# DA1469x register map
Vendor: Dialog; Series: DA1469x; File version: 1.2
CPU: CM33 r1p0, little endian, no MPU, FPU, 3 interrupt priority bits
Registers are 32-bit, read-write, reset 0x0 unless marked. A register's access mark holds for its fields unless they carry their own. Offsets are from the block's base; [hi:lo] are bit positions.

## QSPIC2 — QSPIC2 registers
Base 0x34000000
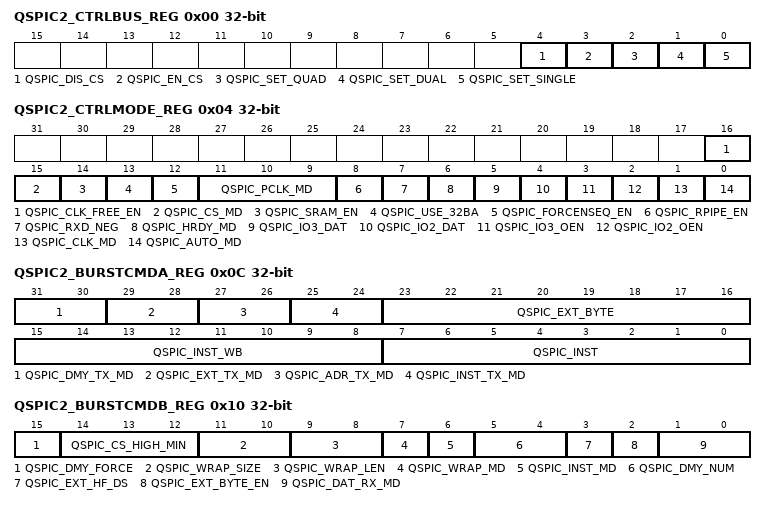
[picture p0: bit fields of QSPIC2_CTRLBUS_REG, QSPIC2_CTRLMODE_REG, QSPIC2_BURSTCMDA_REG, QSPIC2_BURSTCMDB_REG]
0x00 QSPIC2_CTRLBUS_REG — SPI Bus control register for the Manual mode
  [4] QSPIC_DIS_CS wo — Write 1 to disable the chip select (active low) when the controller is in Manual mode.
  [3] QSPIC_EN_CS wo — Write 1 to enable the chip select (active low) when the controller is in Manual mode.
  [2] QSPIC_SET_QUAD wo — Write 1 to set the bus mode in Quad mode when the controller is in Manual mode.
  [1] QSPIC_SET_DUAL wo — Write 1 to set the bus mode in Dual mode when the controller is in Manual mode.
  [0] QSPIC_SET_SINGLE wo — Write 1 to set the bus mode in Single SPI mode when the controller is in Manual mode.
0x04 QSPIC2_CTRLMODE_REG — Mode control register
  [16] QSPIC_CLK_FREE_EN — Controls the behavior of the QSPI_SCK when the QSPI_CS is high and the QSPIC_CS_MD=1. 0: Is produced one QSPI_SCK clock pulse after each 0 to 1 transition in the QSPI_CS. 1: The QSPI_SCK clock remains always active, while the QSPI_CS is inactive. This setting has meaning only when the QSPIC_CS_MD=1.
  [15] QSPIC_CS_MD — Controls the clock edge with which is produced the QSPI_CS signal. 0: The QSPI_CS is produced with the rising edge of the QSPI_SCK. The QSPI_SCK is always inactive while the QSPI_CS is high. 1: The QSPI_CS is produced with the falling edge of the QSPI_SCK. The behavior of the QSPI_SCK while the QSPI_CS is high, is controlled by the QSPIC_CLK_FREE_EN.
  [14] QSPIC_SRAM_EN — Defines the type of the external device that is connected on the QSPIC controller 0: The external memory device is a serial Flash 1: The external memory device is a serial SRAM When the external device is a serial SRAM, the erase suspend/ resume functionality of the controller is disabled. In this case the writing of the QSPIC_ERASECTRL_REG[QSPIC_ERASE_EN] bit has no effect. Also, the memory space where the external device is mapped, is considered as writable.
  [13] QSPIC_USE_32BA — Controls the length of the address that the external memory device uses. 0: The external memory device uses 24 bits address. 1: The external memory device uses 32 bits address. The controller uses this bit in order to decide the number of the address bytes that has to transfer to the external device during Auto mode.
  [12] QSPIC_FORCENSEQ_EN — Controls the way with which is addressed by the QSPI controller a burst request from the AMBA bus. 0: The controller translates a burst access on the AMBA bus as a burst access on the QSPI bus. That results to the minimum number of command/address phases. 1: The controller will split a burst access on the AMBA bus into a number of single accesses on the QSPI bus. That results to a separate command for each beat of the burst. E.g a 4-beat word incremental AMBA read access will be split into 4 different sequences on the QSPI bus: command/address/extra clock/read data. The QSPI_CS will be low only for the time that is needed for each of these single access. This configuration bit is usefull when the clock frequency of the QSPI bus is much higher than the clock of the AMBA bus. In this case the interval for which the CS remains low is minimized, achieving lower power dissipation with respect of the case where the QSPIC_FORCENSEQ_EN=0, at cost of performance.
  [11:9] QSPIC_PCLK_MD — Controls the read pipe clock delay relative to the falling edge of QSPI_SCK. Refer to QSPI Timing for timing parameters
  [8] QSPIC_RPIPE_EN — Controls the use of the data read pipe. 0: The read pipe is disabled, the sampling clock is defined according to the QSPIC_RXD_NEG setting. 1: The read pipe is enabled. The delay of the sampling clock is defined according to the QSPI_PCLK_MD setting. (Recommended)
  [7] QSPIC_RXD_NEG — Defines the clock edge that is used for the capturing of the received data, when the read pipe is not active (QSPIC_RPIPE_EN = 0). 0: Sampling of the received data with the positive edge of the QSPI_SCK 1: Sampling of the received data with the negative edge of the QSPI_SCK The internal QSPI_SCK clock that is used by the controller for the capturing of the received data has a skew in respect of the QSPI_SCK that is received by the external memory device. In order to be improved the timing requirements of the read path, the controller supports a read pipe register with programmable clock delay. See also the QSPIC_RPIPE_EN register.
  [6] QSPIC_HRDY_MD — This configuration bit is useful when the frequency of the QSPI clock is much lower than the clock of the AMBA bus, in order to not locks the AMBA bus for a long time. 0: Adds wait states via hready signal when an access is performed on the QSPIC_WRITEDATA, QSPIC_READDATA and QSPIC_DUMMYDATA registers. It is not needed to checked the QSPIC_BUSY of the QSPIC_STATUS_REG. 1: The controller don't adds wait states via the hready signal, when is performed access on the QSPIC_WRITEDATA, QSPIC_READDATA and QSPIC_DUMMYDATA registers. The QSPIC_BUSY bit of the QSPIC_STATUS_REG must be checked in order to be detected the completion of the requested access. It is applicable only when the controller is in Manual mode. In the case of the Auto mode, the controller always adds wait states via the hready signal.
  [5] QSPIC_IO3_DAT — The value of QSPI_IO3 pad if QSPI_IO3_OEN is 1
  [4] QSPIC_IO2_DAT — The value of QSPI_IO2 pad if QSPI_IO2_OEN is 1
  [3] QSPIC_IO3_OEN — QSPI_IO3 output enable. Use this only in SPI or Dual SPI mode to control /HOLD signal. When the Auto Mode is selected (QSPIC_AUTO_MD = 1) and the QUAD SPI is used, set this bit to zero. 0: The QSPI_IO3 pad is input. 1: The QSPI_IO3 pad is output.
  [2] QSPIC_IO2_OEN — QSPI_IO2 output enable. Use this only in SPI or Dual SPI mode to control /WP signal. When the Auto Mode is selected (QSPIC_AUTO_MD = 1) and the QUAD SPI is used, set this bit to zero. 0: The QSPI_IO2 pad is input. 1: The QSPI_IO2 pad is output.
  [1] QSPIC_CLK_MD — Mode of the generated QSPI_SCK clock 0: Use Mode 0 for the QSPI_CLK. The QSPI_SCK is low when QSPI_CS is high. 1: Use Mode 3 for the QSPI_CLK. The QSPI_SCK is high when QSPI_CS is high. See also the register QSPIC_CS_MD and the QSPIC_CLK_FREE_EN
  [0] QSPIC_AUTO_MD — Mode of operation 0: The Manual Mode is selected. 1: The Auto Mode is selected. During an erasing the QSPIC_AUTO_MD goes in read only mode (see QSPIC_ERASE_EN)
0x08 QSPIC2_RECVDATA_REG (reset mask 0x7FFFFFFF) — Received data for the Manual mode
  [31:0] QSPIC_RECVDATA ro — This register contains the received data when the QSPIC_READDATA_REG register is used in Manual mode, in order to be retrieved data from the external memory device and QSPIC_HRDY_MD=1 && QSPIC_BUSY=0.
0x0C QSPIC2_BURSTCMDA_REG (reset mask 0x7FFFFFFF) — The way of reading in Auto mode (command register A)
  [31:30] QSPIC_DMY_TX_MD — It describes the mode of the SPI bus during the Dummy bytes phase. 0x0: Single SPI 0x1: Dual 0x2: Quad 0x3: Reserved
  [29:28] QSPIC_EXT_TX_MD — It describes the mode of the SPI bus during the Extra Byte phase. 0x0: Single SPI 0x1: Dual 0x2: Quad 0x3: Reserved
  [27:26] QSPIC_ADR_TX_MD — It describes the mode of the SPI bus during the address phase. 0x0: Single SPI 0x1: Dual 0x2: Quad 0x3: Reserved
  [25:24] QSPIC_INST_TX_MD — It describes the mode of the SPI bus during the instruction phase. 0x0: Single SPI 0x1: Dual 0x2: Quad 0x3: Reserved
  [23:16] QSPIC_EXT_BYTE — The value of an extra byte which will be transferred after address (only if QSPIC_EXT_BYTE_EN= 1). Usually this is the Mode Bits in Dual/Quad SPI I/O instructions.
  [15:8] QSPIC_INST_WB — Instruction Value for Wrapping Burst. This value is the selected instruction when QSPIC_WRAP_MD is equal to 1 and the access is a wrapping burst of length and size described by the bit fields QSPIC_WRAP_LEN and QSPIC_WRAP_SIZE respectively.
  [7:0] QSPIC_INST — Instruction Value for Incremental Burst or Single read access. This value is the selected instruction at the cases of incremental burst or single read access. Also this value is used when a wrapping burst is not supported (QSPIC_WRAP_MD)
0x10 QSPIC2_BURSTCMDB_REG — The way of reading in Auto mode (command register B)
  [15] QSPIC_DMY_FORCE — By setting this bit, the number of dummy bytes is forced to be equal to 3. In this case the QSPIC_DMY_NUM field is overruled and has no function. 0: The number of dummy bytes is controlled by the QSPIC_DMY_NUM field 1: Three dummy bytes are used. The QSPIC_DMY_NUM is overruled.
  [14:12] QSPIC_CS_HIGH_MIN — Between the transmission of two different instructions to the flash memory, the qspi bus stays in idle state (QSPI_CS high) for at least this number of QSPI_SCK clock cycles. See the QSPIC_ERS_CS_HI and the QSPIC_WR_CS_HIGH_MIN registers for some exceptions.
  [11:10] QSPIC_WRAP_SIZE — It describes the selected data size of a wrapping burst (QSPIC_WRAP_MD). 0x0: Byte access (8-bits) 0x1: Half word access (16 bits) 0x2: Word access (32-bits) 0x3: Reserved
  [9:8] QSPIC_WRAP_LEN — It describes the selected length of a wrapping burst (QSPIC_WRAP_MD). 0x0: 4 beat wrapping burst 0x1: 8 beat wrapping burst 0x2: 16 beat wrapping burst 0x3: Reserved
  [7] QSPIC_WRAP_MD — Wrap mode 0: The QSPIC_INST is the selected instruction at any access. 1: The QSPIC_INST_WB is the selected instruction at any wrapping burst access of length and size described by the registers QSPIC_WRAP_LEN and QSPIC_WRAP_SIZE respectively. In all other cases the QSPIC_INST is the selected instruction. Use this feature only when the serial FLASH memory supports a special instruction for wrapping burst access.
  [6] QSPIC_INST_MD — Instruction mode 0: Transmit instruction at any burst access. 1: Transmit instruction only in the first access after the selection of Auto Mode.
  [5:4] QSPIC_DMY_NUM — Number of Dummy Bytes 0x0: Zero Dummy Bytes (Don't Send Dummy Bytes) 0x1: Send 1 Dummy Byte 0x2: Send 2 Dummy Bytes 0x3: Send 4 Dummy Bytes When QSPIC_DMY_FORCE is enabled, the QSPIC_DMY_NUM is overruled. In this case the number of dummy bytes is defined by the QSPIC_DMY_FORCE and is equal to 3, independent of the value of the QSPIC_DMY_NUM.
  [3] QSPIC_EXT_HF_DS — Extra Half Disable Output 0: if QSPIC_EXT_BYTE_EN=1 then transmit the complete QSPIC_EXT_BYTE 1: if QSPIC_EXT_BYTE_EN=1 then disable (hi-z) output during the transmission of bits [3:0] of QSPIC_EXT_BYTE
  [2] QSPIC_EXT_BYTE_EN — Extra Byte Enable 0: Don't Send QSPIC_EXT_BYTE 1: Send QSPIC_EXT_BYTE
  [1:0] QSPIC_DAT_RX_MD — It describes the mode of the SPI bus during the data phase. 0x0: Single SPI 0x1: Dual 0x2: Quad 0x3: Reserved
0x14 QSPIC2_STATUS_REG — The status register of the QSPI controller
  [0] QSPIC_BUSY ro — The status of the SPI Bus. 0: The SPI Bus is idle 1: The SPI Bus is active. Read data, write data or dummy data activity is in progress. Has meaning only in Manual mode and only when QSPIC_HRDY_MD = 1.
0x18 QSPIC2_WRITEDATA_REG (reset mask 0x7FFFFFFF) — Write data to SPI Bus for the Manual mode
  [31:0] QSPIC_WRITEDATA wo — Writing to this register is generating a data transfer from the controller to the external memory device. The data written in this register, is then transferred to the memory using the selected mode of the SPI bus (SPI, Dual SPI, Quad SPI). The data size of the access to this register can be 32-bits / 16-bits/ 8-bits and is equal to the number of the transferred bits. This register has meaning only when the controller is in Manual mode.
0x1C QSPIC2_READDATA_REG (reset mask 0x7FFFFFFF) — Read data from SPI Bus for the Manual mode
  [31:0] QSPIC_READDATA ro — A read access at this register generates a data transfer from the external memory device to the QSPIC controller. The data is transferred using the selected mode of the SPI bus (SPI, Dual SPI, Quad SPI). The data size of the access to this register can be 32-bits / 16-bits / 8-bits and is equal to the number of the transferred bits. This register has meaning only when the controller is in Manual mode.
0x20 QSPIC2_DUMMYDATA_REG (reset mask 0x7FFFFFFF) — Send dummy clocks to SPI Bus for the Manual mode
  [31:0] QSPIC_DUMMYDATA wo — Writing to this register generates a number of clock pulses to the SPI bus. During the last clock of this activity in the SPI bus, the QSPI_IOx data pads are in hi-z state. The data size of the access to this register can be 32-bits / 16-bits/ 8-bits. The number of generated pulses is equal to: (size of AHB bus access) / (size of SPI bus). The size of SPI bus is equal to 1, 2 or 4 for Single, Dual or Quad SPI mode respectively. This register has meaning only when the controller is in Manual mode.
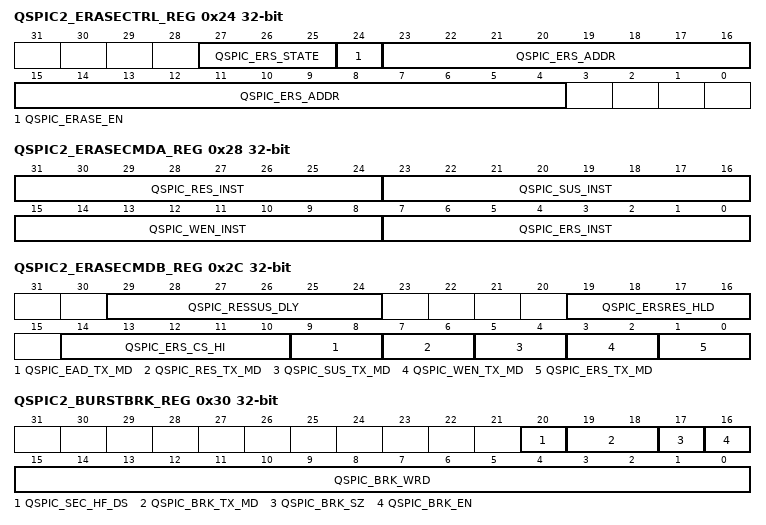
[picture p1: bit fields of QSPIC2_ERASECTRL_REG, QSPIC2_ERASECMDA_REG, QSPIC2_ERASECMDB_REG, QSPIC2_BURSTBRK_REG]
0x24 QSPIC2_ERASECTRL_REG — Erase control register
  [27:25] QSPIC_ERS_STATE ro — It shows the progress of sector/block erasing (read only). 0x0: No Erase. 0x1: Pending erase request 0x2: Erase procedure is running 0x3: Suspended Erase procedure 0x4: Finishing the Erase procedure 0x5..0x7: Reserved
  [24] QSPIC_ERASE_EN — This bit has meaning only when the external device is a serial FLASH (QSPIC_SRAM_EN=0). During Manual mode (QSPIC_AUTO_MD = 0) : This bit is in read only mode. During Auto mode (QSPIC_AUTO_MD = 1). To request the erasing of the block/sector (QSPIC_ERS_ADDR, 12'b0) write 1 to this bit. This bit is cleared automatically with the end of the erasing. Until the end of erasing the QSPIC_ERASE_EN remains in read only mode. During the same period of time the controller remains in Auto Mode (QSPIC_AUTO_MD goes in read only mode). In the case where the external device is a serial SRAM (QSPIC_SRAM_EN=1) this bit is in read only mode.
  [23:4] QSPIC_ERS_ADDR — Defines the address of the block/sector that is requested to be erased. If QSPIC_USE_32BA = 0 (24 bits addressing), bits QSPIC_ERASECTRL_REG[23-12] determine the block/ sector address bits [23-12]. QSPIC_ERASECTRL_REG[11-4] are ignored by the controller. If QSPIC_USE_32BA = 1 (32 bits addressing) bits QSPIC_ERASECTRL_REG[23-4] determine the block / sectors address bits [31:12]
0x28 QSPIC2_ERASECMDA_REG (reset mask 0x7FFFFFFF) — The way of erasing in Auto mode (command register A)
  [31:24] QSPIC_RES_INST — The code value of the erase resume instruction
  [23:16] QSPIC_SUS_INST — The code value of the erase suspend instruction.
  [15:8] QSPIC_WEN_INST — The code value of the write enable instruction.
  [7:0] QSPIC_ERS_INST — The code value of the erase instruction.
0x2C QSPIC2_ERASECMDB_REG — The way of erasing in Auto mode (command register B)
  [29:24] QSPIC_RESSUS_DLY — Defines a timer that counts the minimum allowed delay between an erase suspend command and the previous erase resume command (or the initial erase command). 0x00: Dont wait. The controller starts immediately to suspend the erase procedure. 0x01..0x3F: The controller waits for at least this number of 288 KHz clock cycles before the suspension of erasing. Time starts counting after the end of the previous erase resume command (or the initial erase command)
  [19:16] QSPIC_ERSRES_HLD — The controller must stay without flash memory reading requests for this number of AMBA hclk clock cycles, before to perform the command of erase or erase resume. Allowable range : 0xF - 0x0
  [14:10] QSPIC_ERS_CS_HI — After the execution of instructions: write enable, erase, erase suspend and erase resume, the QSPI_CS remains high for at least this number of QSPI_SCK clock cycles.
  [9:8] QSPIC_EAD_TX_MD — The mode of the SPI Bus during the address phase of the erase instruction 0x0: Single SPI 0x1: Dual 0x2: Quad 0x3: Reserved
  [7:6] QSPIC_RES_TX_MD — The mode of the SPI Bus during the transmission of the resume instruction 0x0: Single SPI 0x1: Dual 0x2: Quad 0x3: Reserved
  [5:4] QSPIC_SUS_TX_MD — The mode of the SPI Bus during the transmission of the suspend instruction. 0x0: Single SPI 0x1: Dual 0x2: Quad 0x3: Reserved
  [3:2] QSPIC_WEN_TX_MD — The mode of the SPI Bus during the transmission of the write enable instruction. 0x0: Single SPI 0x1: Dual 0x2: Quad 0x3: Reserved
  [1:0] QSPIC_ERS_TX_MD — The mode of the SPI Bus during the instruction phase of the erase instruction 0x0: Single SPI 0x1: Dual 0x2: Quad 0x3: Reserved
0x30 QSPIC2_BURSTBRK_REG — Read break sequence in Auto mode
  [20] QSPIC_SEC_HF_DS — Disable output during the transmission of the second half (QSPIC_BRK_WRD[3:0]). Setting this bit is only useful if QSPIC_BRK_EN =1 and QSPIC_BRK_SZ= 1. 0: The controller drives the SPI bus during the transmission of the QSPIC_BRK_WRD[3:0]. 1: The controller leaves the SPI bus in Hi-Z during the transmission of the QSPIC_BRK_WORD[3:0].
  [19:18] QSPIC_BRK_TX_MD — The mode of the SPI Bus during the transmission of the read break sequence. 0x0: Single SPI 0x1: Dual 0x2: Quad 0x3: Reserved
  [17] QSPIC_BRK_SZ — The size of the read break sequence. 0: One byte (Send QSPIC_BRK_WRD[15:8]) 1: Two bytes (Send QSPIC_BRK_WRD[15:0])
  [16] QSPIC_BRK_EN — Controls the application of a special command (read break sequence) that is used in order to force the device to abandon the continuous read mode. 0: The special command is not applied 1: The special command is applied This special command is applied by the controller to the external device under the following conditions: - the controller is in Auto mode - the QSPIC_INST_MD = 1 - the previous command that has been applied in the external device was read - the controller want to apply to the external device a command different than the read.
  [15:0] QSPIC_BRK_WRD — This is the value of a special command (read break sequence) that is applied by the controller to the external memory device, in order to force the memory device to abandon the continuous read mode.
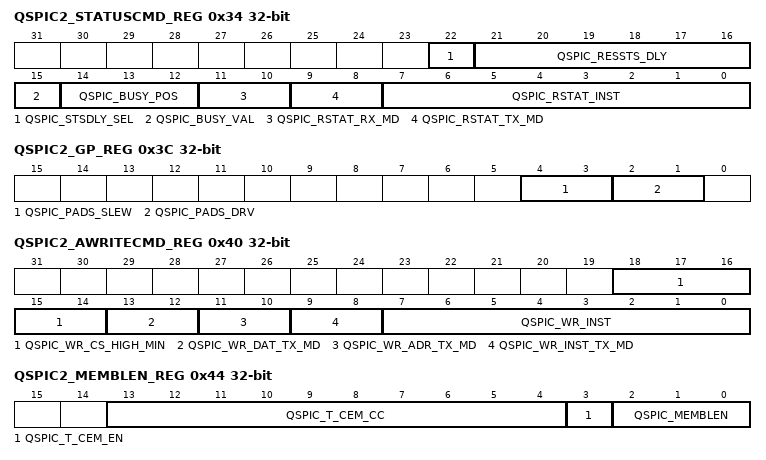
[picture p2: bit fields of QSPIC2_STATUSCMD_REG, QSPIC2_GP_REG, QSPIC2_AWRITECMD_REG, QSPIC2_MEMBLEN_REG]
0x34 QSPIC2_STATUSCMD_REG — The way of reading the status of external device in Auto mode
  [22] QSPIC_STSDLY_SEL — Defines the timer which is used to count the delay that it has to wait before to read the FLASH Status Register, after an erase or an erase resume command. 0: The delay is controlled by the QSPIC_RESSTS_DLY which counts on the qspi clock. 1: The delay is controlled by the QSPIC_RESSUS_DLY which counts on the 288 kHz clock.
  [21:16] QSPIC_RESSTS_DLY — Defines a timer that counts the minimum required delay between the reading of the status register and of the previous erase or erase resume instruction. 0x00: Dont wait. The controller starts to reading the Flash memory status register immediately. 0x01..0x3F: The controller waits for at least this number of QSPI_CLK cycles and afterwards it starts to reading the Flash memory status register. The timer starts to count after the end of the previous erase or erase resume command. The actual timer that will be used by the controller before the reading of the Flash memory status register is defined by the QSPIC_STSDLY_SEL.
  [15] QSPIC_BUSY_VAL — Defines the value of the Busy bit which means that the flash is busy. 0: The flash is busy when the Busy bit is equal to 0. 1: The flash is busy when the Busy bit is equal to 1.
  [14:12] QSPIC_BUSY_POS — Defines the bit of the Flash status register which represents the Busy bit (0x7 - 0x0).
  [11:10] QSPIC_RSTAT_RX_MD — The mode of the SPI Bus during the reception phase of the read status instruction, where the value of status register is retrieved. 0x0: Single SPI 0x1: Dual 0x2: Quad 0x3: Reserved
  [9:8] QSPIC_RSTAT_TX_MD — The mode of the SPI Bus during the instruction phase of the read status instruction. 0x0: Single SPI 0x1: Dual 0x2: Quad 0x3: Reserved
  [7:0] QSPIC_RSTAT_INST — The code value of the read status instruction. It is transmitted during the instruction phase of the read status instruction.
0x38 QSPIC2_CHCKERASE_REG (reset mask 0x7FFFFFFF) — Check erase progress in Auto mode
  [31:0] QSPIC_CHCKERASE wo — Writing any value to this register during erasing, forces the controller to read the flash memory status register. Depending on the value of the Busy bit, it updates the QSPIC_ERASE_EN. This register has meaning only when the controller is in Auto mode and there is an erase in progress (QSPIC_ERASE_EN =1). It has no meaning when the external device is a serial SRAM.
0x3C QSPIC2_GP_REG — General purpose QSPIC2 register
  [4:3] QSPIC_PADS_SLEW — QSPI pads slew rate control. Indicative values under certain conditions: 0x0 : Rise=1.7 V/ns, Fall=1.9 V/ns (weak) 0x1 : Rise=2.0 V/ns, Fall=2.3 V/ns 0x2 : Rise=2.3 V/ns, Fall=2.6 V/ns 0x3 : Rise=2.4 V/ns, Fall=2.7 V/ns (strong) Conditions: FLASH pin capacitance 6pF, Vcc=1.8V, T=25C and Idrive=16mA
  [2:1] QSPIC_PADS_DRV — QSPI pads drive current 0x0 : 4 mA 0x1 : 8 mA 0x2 : 12 mA 0x3 : 16 mA
0x40 QSPIC2_AWRITECMD_REG — The way of writing in Auto mode when the external device is a serial SRAM
  [18:14] QSPIC_WR_CS_HIGH_MIN — After the execution of the write command, the QSPI_CS remains high for at least this number of QSPI_SCK clock cycles.
  [13:12] QSPIC_WR_DAT_TX_MD — The mode of the SPI Bus during the data phase of the write command. 0x0: Single SPI 0x1: Dual 0x2: Quad 0x3: Reserved
  [11:10] QSPIC_WR_ADR_TX_MD — The mode of the SPI Bus during the adress phase of the write command. 0x0: Single SPI 0x1: Dual 0x2: Quad 0x3: Reserved
  [9:8] QSPIC_WR_INST_TX_MD — The mode of the SPI Bus during the instruction phase of the write command. 0x0: Single SPI 0x1: Dual 0x2: Quad 0x3: Reserved
  [7:0] QSPIC_WR_INST — This is the value of the instruction that is used, in order to be programmed the external SRAM device.
0x44 QSPIC2_MEMBLEN_REG — External memory burst length configuration
  [13:4] QSPIC_T_CEM_CC — Defines the maximum allowed time tCEM for which the QSPIC_CS can stay active (QSPI_CS=0). It has meaning only when QSPIC_T_CEM_EN is equal to 1. See also the description of the QSPIC_T_CEM_EN for more details. The tCEM is expressed in number of qspi clock cycles and can be calculated as follows : tCEM / (qspi_clock_period) If the result of the above equation is higher than 0x3FF, use the value 0x3FF.
  [3] QSPIC_T_CEM_EN — This bit enables the controlling of the maximum time tCEM for which the QSPI_CS remains active. It has meaning only when the Auto mode is active (QSPIC_AUTO_MD=1) and the external device is a serial SRAM (QSPIC_SRAM_EN=1). In the case where the external device is a serial Flash (QSPIC_SRAM_EN=0) or the controller is in Manual mode (QSPIC_AUTO_MD=0), this field has no any effect. This feature is usefull in the case where the external serial device is a dynamic RAM that requires refresh. If the refresh is applied only when the device is in the idle state (QSPI_CS = 1), the time for which the device remains in the active state (QSPI_CS = 0) should be limited by a maximum threshold. 0:There is no any constraint regarding the maximum allowed time for which the QSPI_CS can stay active. This is the case also when QSPIC_SRAM_EN=0 or QSPIC_AUTO_MD=0. 1:There is a maximum allowed time interval tCEM for which the QSPI_CS can stay active during a burst access (for reading or writting of data). For the controller this is considered as equal to QSPIC_T_CEM_CC x qspi_clock_period. In the case where the data transfer requires the QSPI_CS to stays active for more than QSPIC_T_CEM_CC qspi clock cycles, the QSPI controller splits the access on the SPI bus in more than one bursts, by inserting inactive periods (QSPI_CS = 0) between them. This will cost extra clock cycles for the realization of the original acceess, due to the additional commands that are required in the SPI bus. The value in the QSPIC_T_CEM_CC should be updated every time where the frequency of the qspi clock is modified. The qspi clock frequency should not be decreased more than a lowest frequency. This is the lowest frequency that enables the be performed a 32-bit word read and write access, without violating the tCEM timing requirement (the QSPI controller allows to be performed at least the transferring of one beat of the requested burst, independent of the QSPIC_T_CEM_CC limit).
  [2:0] QSPIC_MEMBLEN — In this register is defined the expected behavior of the external memory device regarding the length of a burst operation : 0x0: The external memory device is capable to implement incremental burst of unspecified length. 0x1: The external memory device implements a wrapping burst of length 4 bytes. 0x2: The external memory device implements a wrapping burst of length 8 bytes. 0x3: The external memory device implements a wrapping burst of length 16 bytes. 0x4: The external memory device implements a wrapping burst of length 32 bytes. 0x5: The external memory device implements a wrapping burst of length 64 bytes. 0x6 - 0x7 : Reserved This setting is used by the QSPI controller when the Auto mode is enabled (QSPIC_AUTO_MD=1), in order to handle the various burst requests of the AHB bus, in respect of the requirements of the external memory device. The external memory device may need to be configured by applying special instruction, in order to be defined the kind of the burst operation. This can be implemented by applying this special instruction with the QSPI controller in Manual mode (QSPIC_AUTO_MD=1). Refer to the datasheet of the external device for more information.
